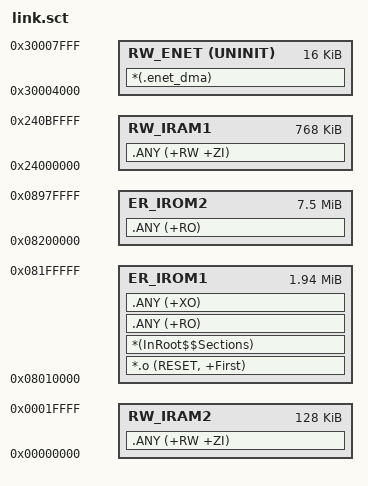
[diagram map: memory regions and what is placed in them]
; *************************************************************
; *** Scatter-Loading Description File generated by uVision ***
; *************************************************************

LR_IROM1 0x08010000 0x001F0000  {    ; load region size_region
  ER_IROM1 0x08010000 0x001F0000  {  ; load address = execution address
   *.o (RESET, +First)
   *(InRoot$$Sections)
   .ANY (+RO)
   .ANY (+XO)
  }
  RW_ENET 0x30004000 UNINIT 0x00004000  {
   *(.enet_dma)
  }
  RW_IRAM1 0x24000000 0x000C0000  {  ; RW data
   .ANY (+RW +ZI)
  }
  RW_IRAM2 0x00000000 0x00020000  {
   .ANY (+RW +ZI)
  }
}

LR_IROM2 0x08200000 0x00780000  {
  ER_IROM2 0x08200000 0x00780000  {  ; load address = execution address
   .ANY (+RO)
  }
}
